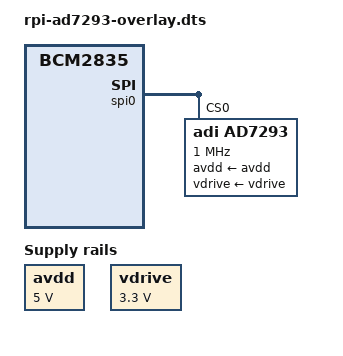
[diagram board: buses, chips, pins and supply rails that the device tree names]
// SPDX-License-Identifier: GPL-2.0
/dts-v1/;
/plugin/;

/ {
	compatible = "brcm,bcm2835";
};

&spidev0 {
	status = "disabled";
};

&{/} {
	avdd: fixedregulator@0 {
		compatible = "regulator-fixed";
		regulator-name = "avdd";
		regulator-min-microvolt = <5000000>;
		regulator-max-microvolt = <5000000>;
		regulator-boot-on;
	};

	vdrive: fixedregulator@1 {
		compatible = "regulator-fixed";
		regulator-name = "vdrive";
		regulator-min-microvolt = <3300000>;
		regulator-max-microvolt = <3300000>;
		regulator-boot-on;
	};
};

&spi0 {
	#address-cells = <1>;
	#size-cells = <0>;
	status = "okay";

	ad7293@0 {
		compatible = "adi,ad7293";
		reg = <0>;
		spi-max-frequency = <1000000>;
		avdd-supply = <&avdd>;
		vdrive-supply = <&vdrive>;
	};
};
